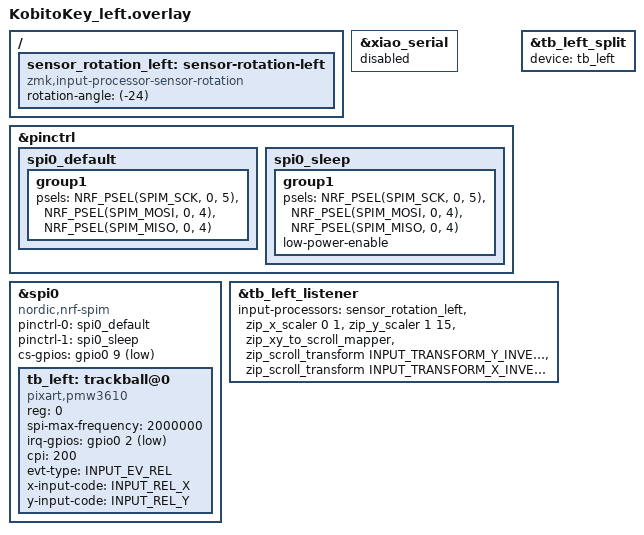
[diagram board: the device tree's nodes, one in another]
#include "kobitokey.dtsi"
#include <zephyr/dt-bindings/input/input-event-codes.h>
#include <input/processors.dtsi>
#include <input/processors/sensor_rotation.dtsi>

&xiao_serial { status = "disabled"; };

&pinctrl {
    spi0_default: spi0_default {
        group1 {
            psels = <NRF_PSEL(SPIM_SCK,  0, 5)>,
                    <NRF_PSEL(SPIM_MOSI, 0, 4)>,
                    <NRF_PSEL(SPIM_MISO, 0, 4)>;
        };
    };
    spi0_sleep: spi0_sleep {
        group1 {
            psels = <NRF_PSEL(SPIM_SCK,  0, 5)>,
                    <NRF_PSEL(SPIM_MOSI, 0, 4)>,
                    <NRF_PSEL(SPIM_MISO, 0, 4)>;
            low-power-enable;
        };
    };
};

&spi0 {
    status = "okay";
    compatible = "nordic,nrf-spim";
    pinctrl-0 = <&spi0_default>;
    pinctrl-1 = <&spi0_sleep>;
    pinctrl-names = "default", "sleep";
    cs-gpios = <&gpio0 9 GPIO_ACTIVE_LOW>;

    tb_left: trackball@0 {
        status = "okay";
        compatible = "pixart,pmw3610";
        reg = <0>;
        spi-max-frequency = <2000000>;
        irq-gpios = <&gpio0 2 (GPIO_ACTIVE_LOW | GPIO_PULL_UP)>;
        cpi = <200>;
        evt-type = <INPUT_EV_REL>;
        x-input-code = <INPUT_REL_X>;
        y-input-code = <INPUT_REL_Y>;
    };
};

/ {
    sensor_rotation_left: sensor-rotation-left {
        compatible = "zmk,input-processor-sensor-rotation";
        status = "okay";
        #input-processor-cells = <0>;
        rotation-angle = <(-24)>;
    };
};

&tb_left_split {
    device = <&tb_left>;
};

&tb_left_listener {
    status = "okay";
    input-processors =
        <&sensor_rotation_left>,
        <&zip_x_scaler 0 1>,
        <&zip_y_scaler 1 15>,
        <&zip_xy_to_scroll_mapper>,
        <&zip_scroll_transform INPUT_TRANSFORM_Y_INVERT>,
        <&zip_scroll_transform INPUT_TRANSFORM_X_INVERT>;
};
